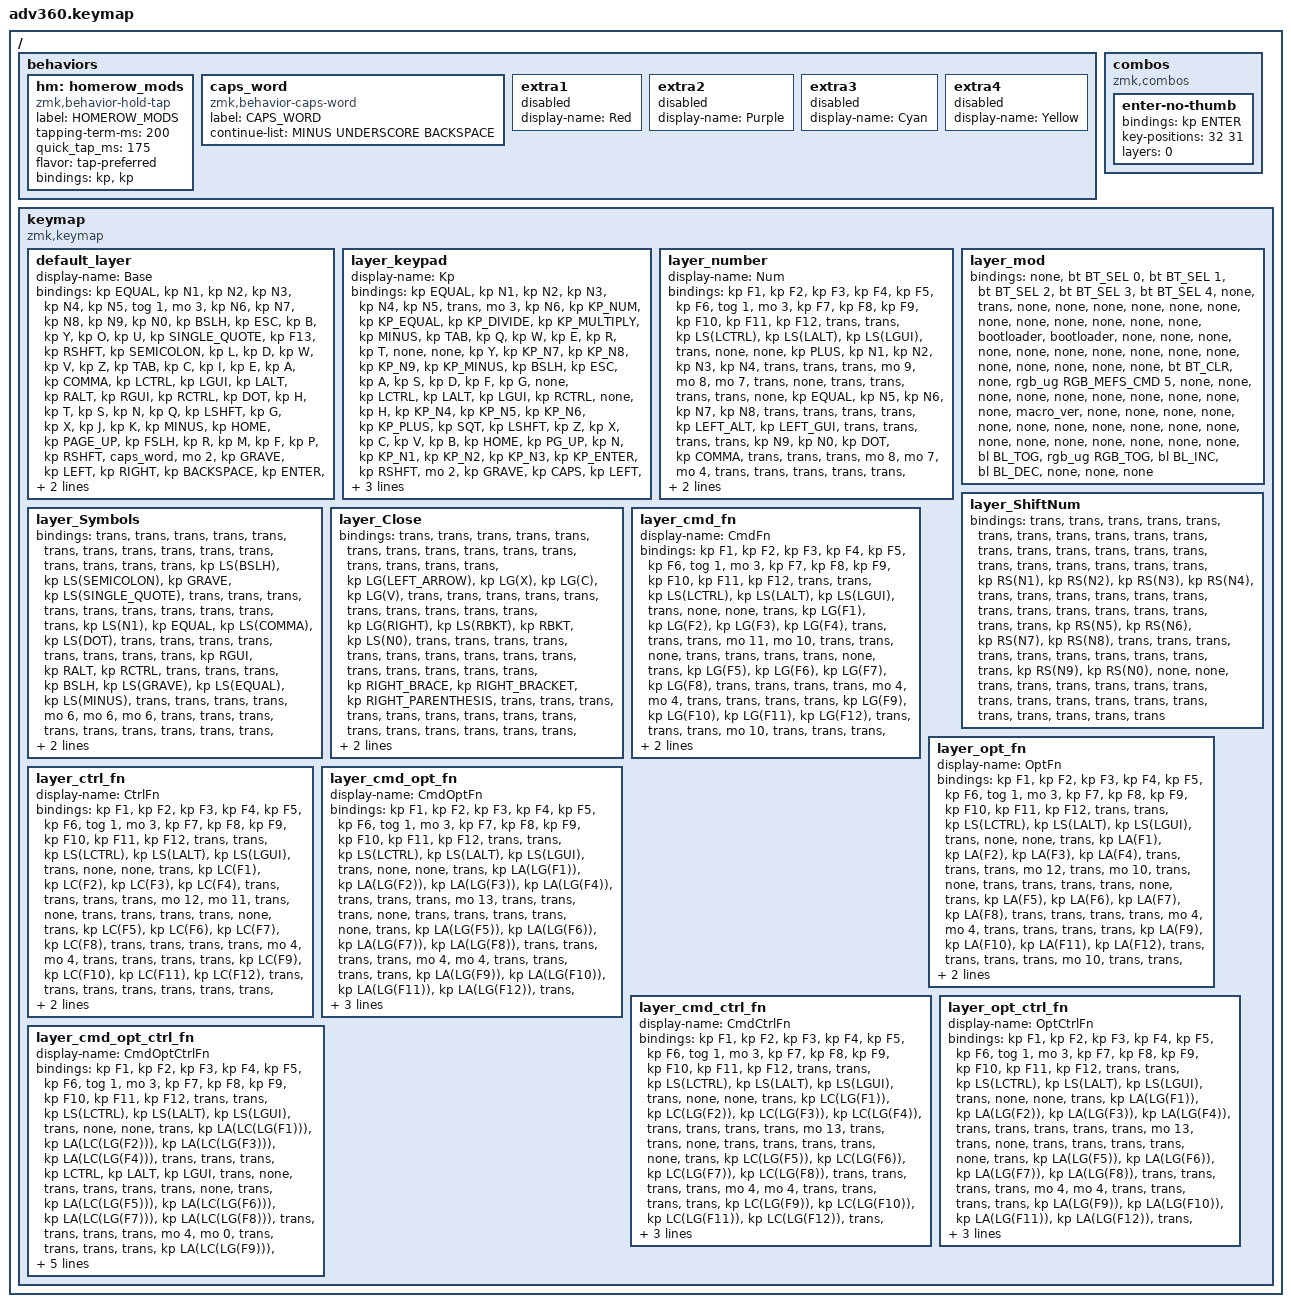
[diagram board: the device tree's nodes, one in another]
/*
 * Copyright (c) 2020 The ZMK Contributors
 *
 * SPDX-License-Identifier: MIT
 */
/* THIS FILE WAS GENERATED!
 *
 * This file was generated automatically. You may or may not want to
 * edit it directly.
 */

#include <dt-bindings/zmk/stp.h>
#include <behaviors.dtsi>
#include <dt-bindings/zmk/backlight.h>
#include <dt-bindings/zmk/bt.h>
#include <dt-bindings/zmk/keys.h>
#include <dt-bindings/zmk/rgb.h>

/ {
    behaviors {
        #include "macros.dtsi"
    #include "version.dtsi"

        hm: homerow_mods {
            compatible = "zmk,behavior-hold-tap";
            label = "HOMEROW_MODS";
            #binding-cells = <2>;
            tapping-term-ms = <200>;
            quick_tap_ms = <175>;
            flavor = "tap-preferred";
            bindings = <&kp>, <&kp>;
        };

        caps_word: caps_word {
            compatible = "zmk,behavior-caps-word";
            label = "CAPS_WORD";
            #binding-cells = <0>;
            continue-list = <MINUS UNDERSCORE BACKSPACE>;
        };

        extra1 {
            display-name = "Red";
            status = "reserved";
        };

        extra2 {
            display-name = "Purple";
            status = "reserved";
        };

        extra3 {
            display-name = "Cyan";
            status = "reserved";
        };

        extra4 {
            display-name = "Yellow";
            status = "reserved";
        };
    };

    combos {
        compatible = "zmk,combos";

        enter-no-thumb {
            bindings = <&kp ENTER>;
            key-positions = <32 31>;
            layers = <0>;
        };
    };

    keymap {
        compatible = "zmk,keymap";

        default_layer {
            display-name = "Base";
            bindings = <
&kp EQUAL   &kp N1  &kp N2     &kp N3    &kp N4     &kp N5            &tog 1                                                            &mo 3       &kp N6         &kp N7  &kp N8    &kp N9    &kp N0  &kp BSLH
&kp ESC     &kp B   &kp Y      &kp O     &kp U      &kp SINGLE_QUOTE  &kp F13                                                           &kp RSHFT   &kp SEMICOLON  &kp L   &kp D     &kp W     &kp V   &kp Z
&kp TAB     &kp C   &kp I      &kp E     &kp A      &kp COMMA         &kp LCTRL      &kp LGUI   &kp LALT      &kp RALT       &kp RGUI   &kp RCTRL   &kp DOT        &kp H   &kp T     &kp S     &kp N   &kp Q
&kp LSHFT   &kp G   &kp X      &kp J     &kp K      &kp MINUS                                   &kp HOME      &kp PAGE_UP                           &kp FSLH       &kp R   &kp M     &kp F     &kp P   &kp RSHFT
&caps_word  &mo 2   &kp GRAVE  &kp LEFT  &kp RIGHT                    &kp BACKSPACE  &kp ENTER  &kp END       &kp PAGE_DOWN  &kp SPACE  &kp DELETE                 &kp UP  &kp DOWN  &kp LBKT  &mo 5   &mo 6
            >;
        };

        layer_keypad {
            display-name = "Kp";
            bindings = <
&kp EQUAL  &kp N1     &kp N2    &kp N3    &kp N4     &kp N5  &trans                                                   &mo 3      &kp N6  &kp KP_NUM  &kp KP_EQUAL  &kp KP_DIVIDE  &kp KP_MULTIPLY  &kp MINUS
&kp TAB    &kp Q      &kp W     &kp E     &kp R      &kp T   &none                                                    &none      &kp Y   &kp KP_N7   &kp KP_N8     &kp KP_N9      &kp KP_MINUS     &kp BSLH
&kp ESC    &kp A      &kp S     &kp D     &kp F      &kp G   &none     &kp LCTRL  &kp LALT      &kp LGUI   &kp RCTRL  &none      &kp H   &kp KP_N4   &kp KP_N5     &kp KP_N6      &kp KP_PLUS      &kp SQT
&kp LSHFT  &kp Z      &kp X     &kp C     &kp V      &kp B                        &kp HOME      &kp PG_UP                        &kp N   &kp KP_N1   &kp KP_N2     &kp KP_N3      &kp KP_ENTER     &kp RSHFT
&mo 2      &kp GRAVE  &kp CAPS  &kp LEFT  &kp RIGHT          &kp BSPC  &kp DEL    &kp END       &kp PG_DN  &kp ENTER  &kp KP_N0          &kp UP      &kp DOWN      &kp KP_DOT     &kp RBKT         &mo 2
            >;
        };

        layer_number {
            display-name = "Num";
            bindings = <
&kp F1  &kp F2  &kp F3         &kp F4        &kp F5        &kp F6  &tog 1                                      &mo 3   &kp F7     &kp F8     &kp F9     &kp F10    &kp F11    &kp F12
&trans  &trans  &kp LS(LCTRL)  &kp LS(LALT)  &kp LS(LGUI)  &trans  &none                                       &none   &kp PLUS   &kp N1     &kp N2     &kp N3     &kp N4     &trans
&trans  &trans  &mo 9          &mo 8         &mo 7         &trans  &none   &trans  &trans      &trans  &trans  &none   &kp EQUAL  &kp N5     &kp N6     &kp N7     &kp N8     &trans
&trans  &trans  &trans         &kp LEFT_ALT  &kp LEFT_GUI  &trans                  &trans      &trans                  &trans     &kp N9     &kp N0     &kp DOT    &kp COMMA  &trans
&trans  &trans  &mo 8          &mo 7         &mo 4                 &trans  &trans  &trans      &trans  &trans  &trans             &kp MINUS  &kp ASTRK  &kp SPACE  &kp SPACE  &trans
            >;
        };

        layer_mod {
            bindings = <
&none  &bt BT_SEL 0  &bt BT_SEL 1  &bt BT_SEL 2  &bt BT_SEL 3  &bt BT_SEL 4  &none                                                  &trans                  &none  &none       &none       &none  &none  &none
&none  &none         &none         &none         &none         &none         &bootloader                                            &bootloader             &none  &none       &none       &none  &none  &none
&none  &none         &none         &none         &none         &none         &none        &none  &none      &bt BT_CLR  &none       &rgb_ug RGB_MEFS_CMD 5  &none  &none       &none       &none  &none  &none
&none  &none         &none         &none         &macro_ver    &none                             &none      &none                                           &none  &none       &none       &none  &none  &none
&none  &none         &none         &none         &none                       &none        &none  &none      &none       &bl BL_TOG  &rgb_ug RGB_TOG                &bl BL_INC  &bl BL_DEC  &none  &none  &none
            >;
        };

        layer_ShiftNum {
            bindings = <
&trans  &trans  &trans  &trans  &trans  &trans  &trans                                      &trans  &trans  &trans      &trans      &trans      &trans      &trans
&trans  &trans  &trans  &trans  &trans  &trans  &trans                                      &trans  &trans  &kp RS(N1)  &kp RS(N2)  &kp RS(N3)  &kp RS(N4)  &trans
&trans  &trans  &trans  &trans  &trans  &trans  &trans  &trans  &trans      &trans  &trans  &trans  &trans  &kp RS(N5)  &kp RS(N6)  &kp RS(N7)  &kp RS(N8)  &trans
&trans  &trans  &trans  &trans  &trans  &trans                  &trans      &trans                  &trans  &kp RS(N9)  &kp RS(N0)  &none       &none       &trans
&trans  &trans  &trans  &trans  &trans          &trans  &trans  &trans      &trans  &trans  &trans          &trans      &trans      &trans      &trans      &trans
            >;
        };

        layer_Symbols {
            bindings = <
&trans  &trans        &trans             &trans         &trans                &trans  &trans                                      &trans  &trans  &trans    &trans        &trans         &trans  &trans
&trans  &kp LS(BSLH)  &kp LS(SEMICOLON)  &kp GRAVE      &kp LS(SINGLE_QUOTE)  &trans  &trans                                      &trans  &trans  &trans    &trans        &trans         &trans  &trans
&trans  &kp LS(N1)    &kp EQUAL          &kp LS(COMMA)  &kp LS(DOT)           &trans  &trans  &trans  &trans      &trans  &trans  &trans  &trans  &kp RGUI  &kp RALT      &kp RCTRL      &trans  &trans
&trans  &kp BSLH      &kp LS(GRAVE)      &kp LS(EQUAL)  &kp LS(MINUS)         &trans                  &trans      &trans                  &trans  &mo 6     &mo 6         &mo 6          &trans  &trans
&trans  &trans        &trans             &trans         &trans                        &trans  &trans  &trans      &trans  &trans  &trans          &mo 6     &kp LEFT_GUI  &kp RIGHT_ALT  &trans  &trans
            >;
        };

        layer_Close {
            bindings = <
&trans  &trans              &trans           &trans             &trans                 &trans  &trans                                      &trans  &trans  &trans  &trans  &trans  &trans  &trans
&trans  &kp LG(LEFT_ARROW)  &kp LG(X)        &kp LG(C)          &kp LG(V)              &trans  &trans                                      &trans  &trans  &trans  &trans  &trans  &trans  &trans
&trans  &kp LG(RIGHT)       &kp LS(RBKT)     &kp RBKT           &kp LS(N0)             &trans  &trans  &trans  &trans      &trans  &trans  &trans  &trans  &trans  &trans  &trans  &trans  &trans
&trans  &trans              &kp RIGHT_BRACE  &kp RIGHT_BRACKET  &kp RIGHT_PARENTHESIS  &trans                  &trans      &trans                  &trans  &trans  &trans  &trans  &trans  &trans
&trans  &trans              &trans           &trans             &trans                         &trans  &trans  &trans      &trans  &trans  &trans          &trans  &trans  &trans  &trans  &trans
            >;
        };

        layer_cmd_fn {
            display-name = "CmdFn";
            bindings = <
&kp F1  &kp F2  &kp F3         &kp F4        &kp F5        &kp F6  &tog 1                                      &mo 3   &kp F7  &kp F8      &kp F9       &kp F10      &kp F11      &kp F12
&trans  &trans  &kp LS(LCTRL)  &kp LS(LALT)  &kp LS(LGUI)  &trans  &none                                       &none   &trans  &kp LG(F1)  &kp LG(F2)   &kp LG(F3)   &kp LG(F4)   &trans
&trans  &trans  &mo 11         &mo 10        &trans        &trans  &none   &trans  &trans      &trans  &trans  &none   &trans  &kp LG(F5)  &kp LG(F6)   &kp LG(F7)   &kp LG(F8)   &trans
&trans  &trans  &trans         &mo 4         &mo 4         &trans                  &trans      &trans                  &trans  &kp LG(F9)  &kp LG(F10)  &kp LG(F11)  &kp LG(F12)  &trans
&trans  &trans  &mo 10         &trans        &trans                &trans  &trans  &trans      &trans  &trans  &trans          &trans      &trans       &trans       &trans       &trans
            >;
        };

        layer_opt_fn {
            display-name = "OptFn";
            bindings = <
&kp F1  &kp F2  &kp F3         &kp F4        &kp F5        &kp F6  &tog 1                                      &mo 3   &kp F7  &kp F8      &kp F9       &kp F10      &kp F11      &kp F12
&trans  &trans  &kp LS(LCTRL)  &kp LS(LALT)  &kp LS(LGUI)  &trans  &none                                       &none   &trans  &kp LA(F1)  &kp LA(F2)   &kp LA(F3)   &kp LA(F4)   &trans
&trans  &trans  &mo 12         &trans        &mo 10        &trans  &none   &trans  &trans      &trans  &trans  &none   &trans  &kp LA(F5)  &kp LA(F6)   &kp LA(F7)   &kp LA(F8)   &trans
&trans  &trans  &trans         &mo 4         &mo 4         &trans                  &trans      &trans                  &trans  &kp LA(F9)  &kp LA(F10)  &kp LA(F11)  &kp LA(F12)  &trans
&trans  &trans  &trans         &mo 10        &trans                &trans  &trans  &trans      &trans  &trans  &trans          &trans      &trans       &trans       &trans       &trans
            >;
        };

        layer_ctrl_fn {
            display-name = "CtrlFn";
            bindings = <
&kp F1  &kp F2  &kp F3         &kp F4        &kp F5        &kp F6  &tog 1                                      &mo 3   &kp F7  &kp F8      &kp F9       &kp F10      &kp F11      &kp F12
&trans  &trans  &kp LS(LCTRL)  &kp LS(LALT)  &kp LS(LGUI)  &trans  &none                                       &none   &trans  &kp LC(F1)  &kp LC(F2)   &kp LC(F3)   &kp LC(F4)   &trans
&trans  &trans  &trans         &mo 12        &mo 11        &trans  &none   &trans  &trans      &trans  &trans  &none   &trans  &kp LC(F5)  &kp LC(F6)   &kp LC(F7)   &kp LC(F8)   &trans
&trans  &trans  &trans         &mo 4         &mo 4         &trans                  &trans      &trans                  &trans  &kp LC(F9)  &kp LC(F10)  &kp LC(F11)  &kp LC(F12)  &trans
&trans  &trans  &trans         &trans        &trans                &trans  &trans  &trans      &trans  &trans  &trans          &trans      &trans       &trans       &trans       &trans
            >;
        };

        layer_cmd_opt_fn {
            display-name = "CmdOptFn";
            bindings = <
&kp F1  &kp F2  &kp F3         &kp F4        &kp F5        &kp F6  &tog 1                                      &mo 3   &kp F7  &kp F8          &kp F9           &kp F10          &kp F11          &kp F12
&trans  &trans  &kp LS(LCTRL)  &kp LS(LALT)  &kp LS(LGUI)  &trans  &none                                       &none   &trans  &kp LA(LG(F1))  &kp LA(LG(F2))   &kp LA(LG(F3))   &kp LA(LG(F4))   &trans
&trans  &trans  &mo 13         &trans        &trans        &trans  &none   &trans  &trans      &trans  &trans  &none   &trans  &kp LA(LG(F5))  &kp LA(LG(F6))   &kp LA(LG(F7))   &kp LA(LG(F8))   &trans
&trans  &trans  &trans         &mo 4         &mo 4         &trans                  &trans      &trans                  &trans  &kp LA(LG(F9))  &kp LA(LG(F10))  &kp LA(LG(F11))  &kp LA(LG(F12))  &trans
&trans  &trans  &trans         &trans        &trans                &trans  &trans  &trans      &trans  &trans  &trans          &trans          &trans           &trans           &trans           &trans
            >;
        };

        layer_cmd_ctrl_fn {
            display-name = "CmdCtrlFn";
            bindings = <
&kp F1  &kp F2  &kp F3         &kp F4        &kp F5        &kp F6  &tog 1                                      &mo 3   &kp F7  &kp F8          &kp F9           &kp F10          &kp F11          &kp F12
&trans  &trans  &kp LS(LCTRL)  &kp LS(LALT)  &kp LS(LGUI)  &trans  &none                                       &none   &trans  &kp LC(LG(F1))  &kp LC(LG(F2))   &kp LC(LG(F3))   &kp LC(LG(F4))   &trans
&trans  &trans  &trans         &mo 13        &trans        &trans  &none   &trans  &trans      &trans  &trans  &none   &trans  &kp LC(LG(F5))  &kp LC(LG(F6))   &kp LC(LG(F7))   &kp LC(LG(F8))   &trans
&trans  &trans  &trans         &mo 4         &mo 4         &trans                  &trans      &trans                  &trans  &kp LC(LG(F9))  &kp LC(LG(F10))  &kp LC(LG(F11))  &kp LC(LG(F12))  &trans
&trans  &trans  &trans         &trans        &trans                &trans  &trans  &trans      &trans  &trans  &trans          &trans          &trans           &trans           &trans           &trans
            >;
        };

        layer_opt_ctrl_fn {
            display-name = "OptCtrlFn";
            bindings = <
&kp F1  &kp F2  &kp F3         &kp F4        &kp F5        &kp F6  &tog 1                                      &mo 3   &kp F7  &kp F8          &kp F9           &kp F10          &kp F11          &kp F12
&trans  &trans  &kp LS(LCTRL)  &kp LS(LALT)  &kp LS(LGUI)  &trans  &none                                       &none   &trans  &kp LA(LG(F1))  &kp LA(LG(F2))   &kp LA(LG(F3))   &kp LA(LG(F4))   &trans
&trans  &trans  &trans         &trans        &mo 13        &trans  &none   &trans  &trans      &trans  &trans  &none   &trans  &kp LA(LG(F5))  &kp LA(LG(F6))   &kp LA(LG(F7))   &kp LA(LG(F8))   &trans
&trans  &trans  &trans         &mo 4         &mo 4         &trans                  &trans      &trans                  &trans  &kp LA(LG(F9))  &kp LA(LG(F10))  &kp LA(LG(F11))  &kp LA(LG(F12))  &trans
&trans  &trans  &trans         &trans        &trans                &trans  &trans  &trans      &trans  &trans  &trans          &trans          &trans           &trans           &trans           &trans
            >;
        };

        layer_cmd_opt_ctrl_fn {
            display-name = "CmdOptCtrlFn";
            bindings = <
&kp F1  &kp F2  &kp F3         &kp F4        &kp F5        &kp F6  &tog 1                                      &mo 3   &kp F7  &kp F8              &kp F9               &kp F10              &kp F11              &kp F12
&trans  &trans  &kp LS(LCTRL)  &kp LS(LALT)  &kp LS(LGUI)  &trans  &none                                       &none   &trans  &kp LA(LC(LG(F1)))  &kp LA(LC(LG(F2)))   &kp LA(LC(LG(F3)))   &kp LA(LC(LG(F4)))   &trans
&trans  &trans  &kp LCTRL      &kp LALT      &kp LGUI      &trans  &none   &trans  &trans      &trans  &trans  &none   &trans  &kp LA(LC(LG(F5)))  &kp LA(LC(LG(F6)))   &kp LA(LC(LG(F7)))   &kp LA(LC(LG(F8)))   &trans
&trans  &trans  &trans         &mo 4         &mo 0         &trans                  &trans      &trans                  &trans  &kp LA(LC(LG(F9)))  &kp LA(LC(LG(F10)))  &kp LA(LC(LG(F11)))  &kp LA(LC(LG(F12)))  &trans
&trans  &trans  &trans         &trans        &trans                &trans  &trans  &trans      &trans  &trans  &trans          &trans              &trans               &trans               &trans               &trans
            >;
        };
    };
};
